# ISD91200B_v1 register map
File version: 1.0
Registers are 32-bit, read-write, reset 0x0 unless marked. A register's access mark holds for its fields unless they carry their own. Offsets are from the block's base; [hi:lo] are bit positions.

## TMR0 — TMR Register Map
Base 0x40010000
Same registers: TMR1 0x40010020
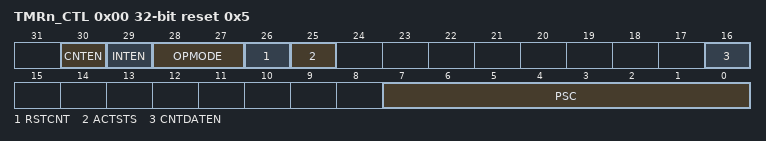
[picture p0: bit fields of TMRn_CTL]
0x00 TMRn_CTL reset 0x5 — Timer Control and Status Register
  [30] CNTEN — Counter Enable Bit
    0=Stops/Suspends counting; 1=Starts counting
  [29] INTEN — Interrupt Enable Bit. If timer interrupt is enabled, the timer asserts its interrupt signal when the count is equal to TIMERx_CMP.
    0=Disable TIMER Interrupt; 1=Enable TIMER Interrupt
  [28:27] OPMODE — Timer Operating Mode
    0=The timer is operating in the one-shot mode. The associated interrupt signal is generated once (if INTEN is enabled) and CNTEN is automatically cleared by hardware; 1=The timer is operating in the periodic mode. The associated interrupt signal is generated periodically (if INTEN is enabled); 3=The timer is operating in continuous counting mode. The associated interrupt signal is generated when CNT = TIMERx_CMP (if INTEN is enabled); however, the 24-bit up-counter counts continuously without reset
  [26] RSTCNT — Counter Reset Bit. Set this bit will reset the timer counter, pre-scale and also force CNTEN to 0.
    0=No effect; 1=Reset Timer's pre-scale counter, internal 24-bit up-counter and CNTEN bit
  [25] ACTSTS ro — Timer Active Status Bit (Read Only). This bit indicates the counter status of timer.
    0=Timer is not active; 1=Timer is active
  [16] CNTDATEN — Data Latch Enable. When CNTDATEN is set, TIMERx_CNT (Timer Data Register) will be updated continuously with the 24-bit up-counter value as the timer is counting.
    0=Timer Data Register update disable; 1=Timer Data Register update enable
  [7:0] PSC — Pre-scale Counter
0x04 TMRn_CMP — Timer Compare Register
  [24:0] CMPDAT — Timer Comparison Value. NOTE1: Never set CMPDAT to 0x000 or 0x001. Timer will not function correctly. NOTE2: Regardless of CEN state, whenever a new value is written to this register, TIMER will restart counting using this new value and abort previous count.
0x08 TMRn_INTSTS — Timer Interrupt Status Register
  [0] TIF — Timer Interrupt Flag. This bit indicates the interrupt status of Timer. TIF bit is set by hardware when the 24-bit counter matches the timer comparison value (CMPDAT). It is cleared by writing 1.
0x0C TMRn_CNT — Timer Data Register
  [23:0] CNT — Timer Data Register. When TIMERx_CTL.CNTDATEN is set to 1, the internal 24-bit timer up-counter value will be latched into CNT. User can read this register for the up-counter value.

## WDT — WDT Register Map
Base 0x40004000
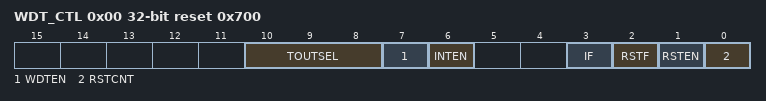
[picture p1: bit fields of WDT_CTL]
0x00 WDT_CTL reset 0x700 — Watchdog Timer Control Register
  [10:8] TOUTSEL — Watchdog Timer Interval Select. These three bits select the timeout interval for the Watchdog timer, a watchdog reset will occur 1024 clock cycles later if WDG not reset. The timeout is given by: Where WDT_CLK is the period of the Watchdog Timer clock source.
  [7] WDTEN — Watchdog Timer Enable
    0=Disable the Watchdog timer (This action will reset the internal counter); 1=Enable the Watchdog timer
  [6] INTEN — Watchdog Timer Interrupt Enable
    0=Disable the Watchdog timer interrupt; 1=Enable the Watchdog timer interrupt
  [3] IF — Watchdog Timer Interrupt Flag. If the Watchdog timer interrupt is enabled, then the hardware will set this bit to indicate that the Watchdog timer interrupt has occurred. If the Watchdog timer interrupt is not enabled, then this bit indicates that a timeout period has elapsed. NOTE: This bit is cleared by writing 1 to this bit.
    0=Watchdog timer interrupt has not occurred; 1=Watchdog timer interrupt has occurred
  [2] RSTF — Watchdog Timer Reset Flag. When the Watchdog timer initiates a reset, the hardware will set this bit. This flag can be read by software to determine the source of reset. Software is responsible to clear it manually by writing 1 to it. If RSTEN is disabled, then the Watchdog timer has no effect on this bit. NOTE: This bit is cleared by writing 1 to this bit.
    0=Watchdog timer reset has not occurred; 1=Watchdog timer reset has occurred
  [1] RSTEN — Watchdog Timer Reset Enable. Setting this bit will enable the Watchdog timer reset function.
    0=Disable Watchdog timer reset function; 1=Enable Watchdog timer reset function
  [0] RSTCNT — Clear Watchdog Timer. Set this bit will clear the Watchdog timer. NOTE: This bit will auto clear after few clock cycle
    0=Writing 0 to this bit has no effect; 1=Reset the contents of the Watchdog timer
